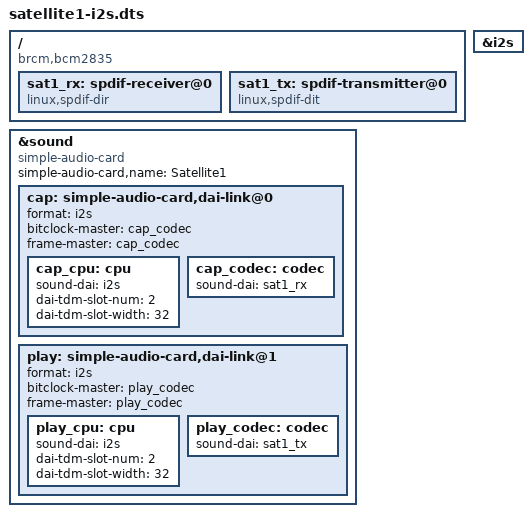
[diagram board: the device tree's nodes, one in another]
/dts-v1/;
/plugin/;

/ {
    compatible = "brcm,bcm2835", "brcm,bcm2711", "brcm,bcm2712";

    fragment@0 {
        target = <&sound>;
        __overlay__ {
            compatible = "simple-audio-card";
            simple-audio-card,name = "Satellite1";
            status = "okay";

            /* Capture: external -> Pi */
            cap: simple-audio-card,dai-link@0 {
                format = "i2s";

                /* Pi is SLAVE: external provides BCLK/LRCLK */
                bitclock-master = <&cap_codec>;
                frame-master    = <&cap_codec>;

                cap_cpu: cpu {
                    sound-dai = <&i2s>;
                    dai-tdm-slot-num   = <2>;
                    dai-tdm-slot-width = <32>;
                };

                cap_codec: codec { sound-dai = <&sat1_rx>; };
            };

            /* Playback: Pi -> external */
            play: simple-audio-card,dai-link@1 {
                format = "i2s";

                /* Pi is SLAVE: external provides BCLK/LRCLK */
                bitclock-master = <&play_codec>;
                frame-master    = <&play_codec>;

                play_cpu: cpu {
                    sound-dai = <&i2s>;
                    dai-tdm-slot-num   = <2>;
                    dai-tdm-slot-width = <32>;
                };

                play_codec: codec { sound-dai = <&sat1_tx>; };
            };
        };
    };

    fragment@1 {
        target-path = "/";
        __overlay__ {
            /* Unique node names to avoid clashes with future overlays */
            sat1_rx: spdif-receiver@0 {
                compatible = "linux,spdif-dir";
                #sound-dai-cells = <0>;
                status = "okay";
            };

            sat1_tx: spdif-transmitter@0 {
                compatible = "linux,spdif-dit";
                #sound-dai-cells = <0>;
                status = "okay";
            };
        };
    };

    fragment@2 {
        target = <&i2s>;
        __overlay__ {
            #sound-dai-cells = <0>;
            status = "okay";
        };
    };
};

